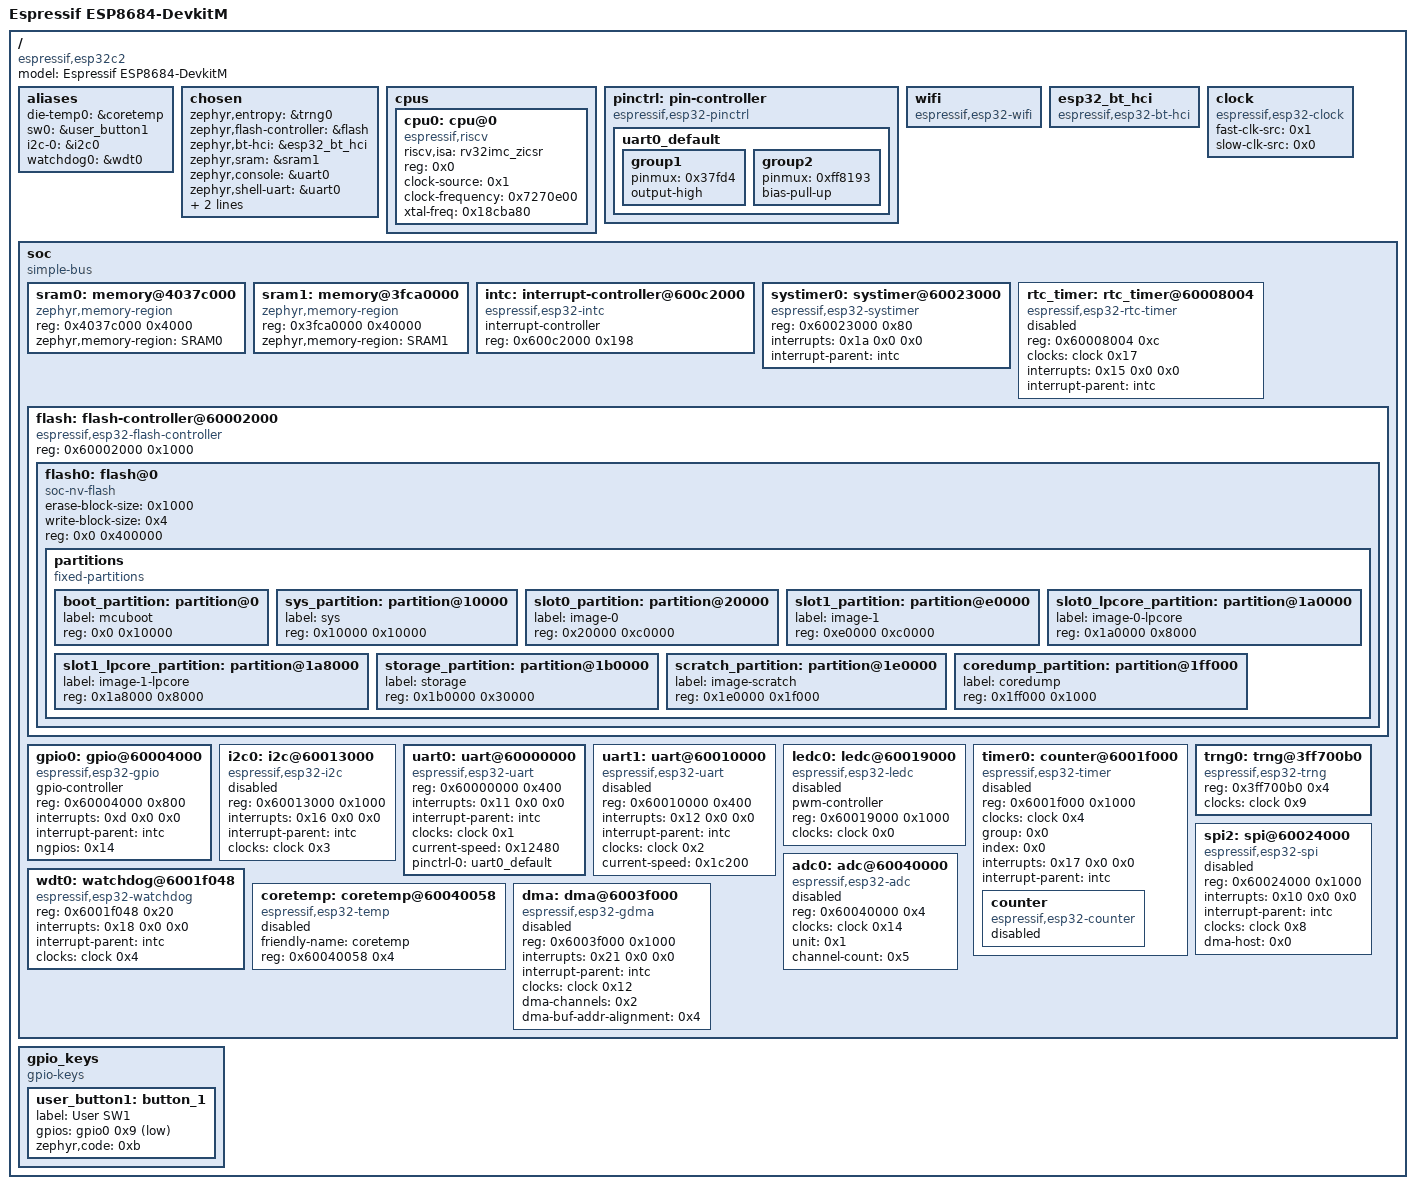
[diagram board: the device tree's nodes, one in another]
/dts-v1/;

/* node '/' defined in zephyr/dts/riscv/espressif/esp32c2/esp32c2_common.dtsi:15 */
/ {
	#address-cells = < 0x1 >;            /* in zephyr/dts/riscv/espressif/esp32c2/esp32c2_common.dtsi:16 */
	#size-cells = < 0x1 >;               /* in zephyr/dts/riscv/espressif/esp32c2/esp32c2_common.dtsi:17 */
	model = "Espressif ESP8684-DevkitM"; /* in zephyr/boards/espressif/esp8684_devkitm/esp8684_devkitm.dts:15 */
	compatible = "espressif,esp32c2";    /* in zephyr/boards/espressif/esp8684_devkitm/esp8684_devkitm.dts:16 */

	/* node '/aliases' defined in zephyr/dts/riscv/espressif/esp32c2/esp32c2_common.dtsi:19 */
	aliases {
		die-temp0 = &coretemp; /* in zephyr/dts/riscv/espressif/esp32c2/esp32c2_common.dtsi:20 */
		sw0 = &user_button1;   /* in zephyr/boards/espressif/esp8684_devkitm/esp8684_devkitm.dts:27 */
		i2c-0 = &i2c0;         /* in zephyr/boards/espressif/esp8684_devkitm/esp8684_devkitm.dts:28 */
		watchdog0 = &wdt0;     /* in zephyr/boards/espressif/esp8684_devkitm/esp8684_devkitm.dts:29 */
	};

	/* node '/chosen' defined in zephyr/dts/riscv/espressif/esp32c2/esp32c2_common.dtsi:23 */
	chosen {
		zephyr,entropy = &trng0;                  /* in zephyr/dts/riscv/espressif/esp32c2/esp32c2_common.dtsi:24 */
		zephyr,flash-controller = &flash;         /* in zephyr/dts/riscv/espressif/esp32c2/esp32c2_common.dtsi:25 */
		zephyr,bt-hci = &esp32_bt_hci;            /* in zephyr/dts/riscv/espressif/esp32c2/esp32c2_common.dtsi:26 */
		zephyr,sram = &sram1;                     /* in zephyr/boards/espressif/esp8684_devkitm/esp8684_devkitm.dts:19 */
		zephyr,console = &uart0;                  /* in zephyr/boards/espressif/esp8684_devkitm/esp8684_devkitm.dts:20 */
		zephyr,shell-uart = &uart0;               /* in zephyr/boards/espressif/esp8684_devkitm/esp8684_devkitm.dts:21 */
		zephyr,flash = &flash0;                   /* in zephyr/boards/espressif/esp8684_devkitm/esp8684_devkitm.dts:22 */
		zephyr,code-partition = &slot0_partition; /* in zephyr/boards/espressif/esp8684_devkitm/esp8684_devkitm.dts:23 */
	};

	/* node '/cpus' defined in zephyr/dts/riscv/espressif/esp32c2/esp32c2_common.dtsi:29 */
	cpus {
		#address-cells = < 0x1 >; /* in zephyr/dts/riscv/espressif/esp32c2/esp32c2_common.dtsi:30 */
		#size-cells = < 0x0 >;    /* in zephyr/dts/riscv/espressif/esp32c2/esp32c2_common.dtsi:31 */

		/* node '/cpus/cpu@0' defined in zephyr/dts/riscv/espressif/esp32c2/esp32c2_common.dtsi:33 */
		cpu0: cpu@0 {
			device_type = "cpu";             /* in zephyr/dts/riscv/espressif/esp32c2/esp32c2_common.dtsi:34 */
			compatible = "espressif,riscv",
			             "riscv";            /* in zephyr/dts/riscv/espressif/esp32c2/esp32c2_common.dtsi:35 */
			riscv,isa = "rv32imc_zicsr";     /* in zephyr/dts/riscv/espressif/esp32c2/esp32c2_common.dtsi:36 */
			reg = < 0x0 >;                   /* in zephyr/dts/riscv/espressif/esp32c2/esp32c2_common.dtsi:37 */
			clock-source = < 0x1 >;          /* in zephyr/dts/riscv/espressif/esp32c2/esp32c2_common.dtsi:38 */
			clock-frequency = < 0x7270e00 >; /* in zephyr/dts/riscv/espressif/esp32c2/esp32c2_common.dtsi:39 */
			xtal-freq = < 0x18cba80 >;       /* in zephyr/dts/riscv/espressif/esp32c2/esp32c2_common.dtsi:40 */
		};
	};

	/* node '/pin-controller' defined in zephyr/dts/riscv/espressif/esp32c2/esp32c2_common.dtsi:44 */
	pinctrl: pin-controller {
		compatible = "espressif,esp32-pinctrl"; /* in zephyr/dts/riscv/espressif/esp32c2/esp32c2_common.dtsi:45 */
		status = "okay";                        /* in zephyr/dts/riscv/espressif/esp32c2/esp32c2_common.dtsi:46 */

		/* node '/pin-controller/uart0_default' defined in zephyr/boards/espressif/esp8684_devkitm/esp8684_devkitm-pinctrl.dtsi:12 */
		uart0_default: uart0_default {
			phandle = < 0x3 >; /* in zephyr/boards/espressif/esp8684_devkitm/esp8684_devkitm.dts:46 */

			/* node '/pin-controller/uart0_default/group1' defined in zephyr/boards/espressif/esp8684_devkitm/esp8684_devkitm-pinctrl.dtsi:13 */
			group1 {
				pinmux = < 0x37fd4 >; /* in zephyr/boards/espressif/esp8684_devkitm/esp8684_devkitm-pinctrl.dtsi:14 */
				output-high;          /* in zephyr/boards/espressif/esp8684_devkitm/esp8684_devkitm-pinctrl.dtsi:15 */
			};

			/* node '/pin-controller/uart0_default/group2' defined in zephyr/boards/espressif/esp8684_devkitm/esp8684_devkitm-pinctrl.dtsi:18 */
			group2 {
				pinmux = < 0xff8193 >; /* in zephyr/boards/espressif/esp8684_devkitm/esp8684_devkitm-pinctrl.dtsi:19 */
				bias-pull-up;          /* in zephyr/boards/espressif/esp8684_devkitm/esp8684_devkitm-pinctrl.dtsi:20 */
			};
		};
	};

	/* node '/wifi' defined in zephyr/dts/riscv/espressif/esp32c2/esp32c2_common.dtsi:49 */
	wifi: wifi {
		compatible = "espressif,esp32-wifi"; /* in zephyr/dts/riscv/espressif/esp32c2/esp32c2_common.dtsi:50 */
		status = "okay";                     /* in zephyr/boards/espressif/esp8684_devkitm/esp8684_devkitm.dts:67 */
	};

	/* node '/esp32_bt_hci' defined in zephyr/dts/riscv/espressif/esp32c2/esp32c2_common.dtsi:54 */
	esp32_bt_hci: esp32_bt_hci {
		compatible = "espressif,esp32-bt-hci"; /* in zephyr/dts/riscv/espressif/esp32c2/esp32c2_common.dtsi:55 */
		status = "okay";                       /* in zephyr/boards/espressif/esp8684_devkitm/esp8684_devkitm.dts:71 */
	};

	/* node '/clock' defined in zephyr/dts/riscv/espressif/esp32c2/esp32c2_common.dtsi:59 */
	clock: clock {
		compatible = "espressif,esp32-clock"; /* in zephyr/dts/riscv/espressif/esp32c2/esp32c2_common.dtsi:60 */
		fast-clk-src = < 0x1 >;               /* in zephyr/dts/riscv/espressif/esp32c2/esp32c2_common.dtsi:61 */
		slow-clk-src = < 0x0 >;               /* in zephyr/dts/riscv/espressif/esp32c2/esp32c2_common.dtsi:62 */
		#clock-cells = < 0x1 >;               /* in zephyr/dts/riscv/espressif/esp32c2/esp32c2_common.dtsi:63 */
		status = "okay";                      /* in zephyr/dts/riscv/espressif/esp32c2/esp32c2_common.dtsi:64 */
		phandle = < 0x2 >;                    /* in zephyr/dts/riscv/espressif/esp32c2/esp32c2_common.dtsi:105 */
	};

	/* node '/soc' defined in zephyr/dts/riscv/espressif/esp32c2/esp32c2_common.dtsi:67 */
	soc {
		#address-cells = < 0x1 >;  /* in zephyr/dts/riscv/espressif/esp32c2/esp32c2_common.dtsi:68 */
		#size-cells = < 0x1 >;     /* in zephyr/dts/riscv/espressif/esp32c2/esp32c2_common.dtsi:69 */
		compatible = "simple-bus"; /* in zephyr/dts/riscv/espressif/esp32c2/esp32c2_common.dtsi:70 */
		ranges;                    /* in zephyr/dts/riscv/espressif/esp32c2/esp32c2_common.dtsi:71 */

		/* node '/soc/memory@4037c000' defined in zephyr/dts/riscv/espressif/esp32c2/esp32c2_common.dtsi:73 */
		sram0: memory@4037c000 {
			compatible = "zephyr,memory-region",
			             "mmio-sram";            /* in zephyr/dts/riscv/espressif/esp32c2/esp32c2_common.dtsi:74 */
			reg = < 0x4037c000 0x4000 >;         /* in zephyr/dts/riscv/espressif/esp32c2/esp32c2_common.dtsi:75 */
			zephyr,memory-region = "SRAM0";      /* in zephyr/dts/riscv/espressif/esp32c2/esp32c2_common.dtsi:76 */
		};

		/* node '/soc/memory@3fca0000' defined in zephyr/dts/riscv/espressif/esp32c2/esp32c2_common.dtsi:79 */
		sram1: memory@3fca0000 {
			compatible = "zephyr,memory-region",
			             "mmio-sram";            /* in zephyr/dts/riscv/espressif/esp32c2/esp32c2_common.dtsi:80 */
			reg = < 0x3fca0000 0x40000 >;        /* in zephyr/dts/riscv/espressif/esp32c2/esp32c2_common.dtsi:81 */
			zephyr,memory-region = "SRAM1";      /* in zephyr/dts/riscv/espressif/esp32c2/esp32c2_common.dtsi:82 */
		};

		/* node '/soc/interrupt-controller@600c2000' defined in zephyr/dts/riscv/espressif/esp32c2/esp32c2_common.dtsi:85 */
		intc: interrupt-controller@600c2000 {
			compatible = "espressif,esp32-intc"; /* in zephyr/dts/riscv/espressif/esp32c2/esp32c2_common.dtsi:86 */
			#address-cells = < 0x0 >;            /* in zephyr/dts/riscv/espressif/esp32c2/esp32c2_common.dtsi:87 */
			#interrupt-cells = < 0x3 >;          /* in zephyr/dts/riscv/espressif/esp32c2/esp32c2_common.dtsi:88 */
			interrupt-controller;                /* in zephyr/dts/riscv/espressif/esp32c2/esp32c2_common.dtsi:89 */
			reg = < 0x600c2000 0x198 >;          /* in zephyr/dts/riscv/espressif/esp32c2/esp32c2_common.dtsi:90 */
			status = "okay";                     /* in zephyr/dts/riscv/espressif/esp32c2/esp32c2_common.dtsi:91 */
			phandle = < 0x1 >;                   /* in zephyr/dts/riscv/espressif/esp32c2/esp32c2_common.dtsi:98 */
		};

		/* node '/soc/systimer@60023000' defined in zephyr/dts/riscv/espressif/esp32c2/esp32c2_common.dtsi:94 */
		systimer0: systimer@60023000 {
			compatible = "espressif,esp32-systimer"; /* in zephyr/dts/riscv/espressif/esp32c2/esp32c2_common.dtsi:95 */
			reg = < 0x60023000 0x80 >;               /* in zephyr/dts/riscv/espressif/esp32c2/esp32c2_common.dtsi:96 */
			interrupts = < 0x1a 0x0 0x0 >;           /* in zephyr/dts/riscv/espressif/esp32c2/esp32c2_common.dtsi:97 */
			interrupt-parent = < &intc >;            /* in zephyr/dts/riscv/espressif/esp32c2/esp32c2_common.dtsi:98 */
			status = "okay";                         /* in zephyr/dts/riscv/espressif/esp32c2/esp32c2_common.dtsi:99 */
		};

		/* node '/soc/rtc_timer@60008004' defined in zephyr/dts/riscv/espressif/esp32c2/esp32c2_common.dtsi:102 */
		rtc_timer: rtc_timer@60008004 {
			reg = < 0x60008004 0xc >;                 /* in zephyr/dts/riscv/espressif/esp32c2/esp32c2_common.dtsi:103 */
			compatible = "espressif,esp32-rtc-timer"; /* in zephyr/dts/riscv/espressif/esp32c2/esp32c2_common.dtsi:104 */
			clocks = < &clock 0x17 >;                 /* in zephyr/dts/riscv/espressif/esp32c2/esp32c2_common.dtsi:105 */
			interrupts = < 0x15 0x0 0x0 >;            /* in zephyr/dts/riscv/espressif/esp32c2/esp32c2_common.dtsi:106 */
			interrupt-parent = < &intc >;             /* in zephyr/dts/riscv/espressif/esp32c2/esp32c2_common.dtsi:107 */
			status = "disabled";                      /* in zephyr/dts/riscv/espressif/esp32c2/esp32c2_common.dtsi:108 */
		};

		/* node '/soc/flash-controller@60002000' defined in zephyr/dts/riscv/espressif/esp32c2/esp32c2_common.dtsi:111 */
		flash: flash-controller@60002000 {
			compatible = "espressif,esp32-flash-controller"; /* in zephyr/dts/riscv/espressif/esp32c2/esp32c2_common.dtsi:112 */
			reg = < 0x60002000 0x1000 >;                     /* in zephyr/dts/riscv/espressif/esp32c2/esp32c2_common.dtsi:113 */
			#address-cells = < 0x1 >;                        /* in zephyr/dts/riscv/espressif/esp32c2/esp32c2_common.dtsi:115 */
			#size-cells = < 0x1 >;                           /* in zephyr/dts/riscv/espressif/esp32c2/esp32c2_common.dtsi:116 */

			/* node '/soc/flash-controller@60002000/flash@0' defined in zephyr/dts/riscv/espressif/esp32c2/esp32c2_common.dtsi:118 */
			flash0: flash@0 {
				compatible = "soc-nv-flash";   /* in zephyr/dts/riscv/espressif/esp32c2/esp32c2_common.dtsi:119 */
				erase-block-size = < 0x1000 >; /* in zephyr/dts/riscv/espressif/esp32c2/esp32c2_common.dtsi:120 */
				write-block-size = < 0x4 >;    /* in zephyr/dts/riscv/espressif/esp32c2/esp32c2_common.dtsi:121 */
				reg = < 0x0 0x400000 >;        /* in zephyr/dts/riscv/espressif/esp32c2/esp8684_mini_h4.dtsi:11 */

				/* node '/soc/flash-controller@60002000/flash@0/partitions' defined in zephyr/dts/vendor/espressif/partitions_0x0_default_2M.dtsi:8 */
				partitions {
					compatible = "fixed-partitions"; /* in zephyr/dts/vendor/espressif/partitions_0x0_default_2M.dtsi:9 */
					#address-cells = < 0x1 >;        /* in zephyr/dts/vendor/espressif/partitions_0x0_default_2M.dtsi:10 */
					#size-cells = < 0x1 >;           /* in zephyr/dts/vendor/espressif/partitions_0x0_default_2M.dtsi:11 */

					/* node '/soc/flash-controller@60002000/flash@0/partitions/partition@0' defined in zephyr/dts/vendor/espressif/partitions_0x0_default_2M.dtsi:13 */
					boot_partition: partition@0 {
						label = "mcuboot";     /* in zephyr/dts/vendor/espressif/partitions_0x0_default_2M.dtsi:14 */
						reg = < 0x0 0x10000 >; /* in zephyr/dts/vendor/espressif/partitions_0x0_default_2M.dtsi:15 */
					};

					/* node '/soc/flash-controller@60002000/flash@0/partitions/partition@10000' defined in zephyr/dts/vendor/espressif/partitions_0x0_default_2M.dtsi:18 */
					sys_partition: partition@10000 {
						label = "sys";             /* in zephyr/dts/vendor/espressif/partitions_0x0_default_2M.dtsi:19 */
						reg = < 0x10000 0x10000 >; /* in zephyr/dts/vendor/espressif/partitions_0x0_default_2M.dtsi:20 */
					};

					/* node '/soc/flash-controller@60002000/flash@0/partitions/partition@20000' defined in zephyr/dts/vendor/espressif/partitions_0x0_default_2M.dtsi:23 */
					slot0_partition: partition@20000 {
						label = "image-0";         /* in zephyr/dts/vendor/espressif/partitions_0x0_default_2M.dtsi:24 */
						reg = < 0x20000 0xc0000 >; /* in zephyr/dts/vendor/espressif/partitions_0x0_default_2M.dtsi:25 */
					};

					/* node '/soc/flash-controller@60002000/flash@0/partitions/partition@e0000' defined in zephyr/dts/vendor/espressif/partitions_0x0_default_2M.dtsi:28 */
					slot1_partition: partition@e0000 {
						label = "image-1";         /* in zephyr/dts/vendor/espressif/partitions_0x0_default_2M.dtsi:29 */
						reg = < 0xe0000 0xc0000 >; /* in zephyr/dts/vendor/espressif/partitions_0x0_default_2M.dtsi:30 */
					};

					/* node '/soc/flash-controller@60002000/flash@0/partitions/partition@1a0000' defined in zephyr/dts/vendor/espressif/partitions_0x0_default_2M.dtsi:33 */
					slot0_lpcore_partition: partition@1a0000 {
						label = "image-0-lpcore";  /* in zephyr/dts/vendor/espressif/partitions_0x0_default_2M.dtsi:34 */
						reg = < 0x1a0000 0x8000 >; /* in zephyr/dts/vendor/espressif/partitions_0x0_default_2M.dtsi:35 */
					};

					/* node '/soc/flash-controller@60002000/flash@0/partitions/partition@1a8000' defined in zephyr/dts/vendor/espressif/partitions_0x0_default_2M.dtsi:38 */
					slot1_lpcore_partition: partition@1a8000 {
						label = "image-1-lpcore";  /* in zephyr/dts/vendor/espressif/partitions_0x0_default_2M.dtsi:39 */
						reg = < 0x1a8000 0x8000 >; /* in zephyr/dts/vendor/espressif/partitions_0x0_default_2M.dtsi:40 */
					};

					/* node '/soc/flash-controller@60002000/flash@0/partitions/partition@1b0000' defined in zephyr/dts/vendor/espressif/partitions_0x0_default_2M.dtsi:43 */
					storage_partition: partition@1b0000 {
						label = "storage";          /* in zephyr/dts/vendor/espressif/partitions_0x0_default_2M.dtsi:44 */
						reg = < 0x1b0000 0x30000 >; /* in zephyr/dts/vendor/espressif/partitions_0x0_default_2M.dtsi:45 */
					};

					/* node '/soc/flash-controller@60002000/flash@0/partitions/partition@1e0000' defined in zephyr/dts/vendor/espressif/partitions_0x0_default_2M.dtsi:48 */
					scratch_partition: partition@1e0000 {
						label = "image-scratch";    /* in zephyr/dts/vendor/espressif/partitions_0x0_default_2M.dtsi:49 */
						reg = < 0x1e0000 0x1f000 >; /* in zephyr/dts/vendor/espressif/partitions_0x0_default_2M.dtsi:50 */
					};

					/* node '/soc/flash-controller@60002000/flash@0/partitions/partition@1ff000' defined in zephyr/dts/vendor/espressif/partitions_0x0_default_2M.dtsi:53 */
					coredump_partition: partition@1ff000 {
						label = "coredump";        /* in zephyr/dts/vendor/espressif/partitions_0x0_default_2M.dtsi:54 */
						reg = < 0x1ff000 0x1000 >; /* in zephyr/dts/vendor/espressif/partitions_0x0_default_2M.dtsi:55 */
					};
				};
			};
		};

		/* node '/soc/gpio@60004000' defined in zephyr/dts/riscv/espressif/esp32c2/esp32c2_common.dtsi:126 */
		gpio0: gpio@60004000 {
			compatible = "espressif,esp32-gpio"; /* in zephyr/dts/riscv/espressif/esp32c2/esp32c2_common.dtsi:127 */
			gpio-controller;                     /* in zephyr/dts/riscv/espressif/esp32c2/esp32c2_common.dtsi:128 */
			#gpio-cells = < 0x2 >;               /* in zephyr/dts/riscv/espressif/esp32c2/esp32c2_common.dtsi:129 */
			reg = < 0x60004000 0x800 >;          /* in zephyr/dts/riscv/espressif/esp32c2/esp32c2_common.dtsi:130 */
			interrupts = < 0xd 0x0 0x0 >;        /* in zephyr/dts/riscv/espressif/esp32c2/esp32c2_common.dtsi:131 */
			interrupt-parent = < &intc >;        /* in zephyr/dts/riscv/espressif/esp32c2/esp32c2_common.dtsi:132 */
			ngpios = < 0x14 >;                   /* in zephyr/dts/riscv/espressif/esp32c2/esp32c2_common.dtsi:138 */
			status = "okay";                     /* in zephyr/boards/espressif/esp8684_devkitm/esp8684_devkitm.dts:55 */
			phandle = < 0x4 >;                   /* in zephyr/boards/espressif/esp8684_devkitm/esp8684_devkitm.dts:37 */
		};

		/* node '/soc/i2c@60013000' defined in zephyr/dts/riscv/espressif/esp32c2/esp32c2_common.dtsi:141 */
		i2c0: i2c@60013000 {
			compatible = "espressif,esp32-i2c"; /* in zephyr/dts/riscv/espressif/esp32c2/esp32c2_common.dtsi:142 */
			#address-cells = < 0x1 >;           /* in zephyr/dts/riscv/espressif/esp32c2/esp32c2_common.dtsi:143 */
			#size-cells = < 0x0 >;              /* in zephyr/dts/riscv/espressif/esp32c2/esp32c2_common.dtsi:144 */
			reg = < 0x60013000 0x1000 >;        /* in zephyr/dts/riscv/espressif/esp32c2/esp32c2_common.dtsi:145 */
			interrupts = < 0x16 0x0 0x0 >;      /* in zephyr/dts/riscv/espressif/esp32c2/esp32c2_common.dtsi:146 */
			interrupt-parent = < &intc >;       /* in zephyr/dts/riscv/espressif/esp32c2/esp32c2_common.dtsi:147 */
			clocks = < &clock 0x3 >;            /* in zephyr/dts/riscv/espressif/esp32c2/esp32c2_common.dtsi:148 */
			status = "disabled";                /* in zephyr/dts/riscv/espressif/esp32c2/esp32c2_common.dtsi:149 */
		};

		/* node '/soc/uart@60000000' defined in zephyr/dts/riscv/espressif/esp32c2/esp32c2_common.dtsi:152 */
		uart0: uart@60000000 {
			compatible = "espressif,esp32-uart"; /* in zephyr/dts/riscv/espressif/esp32c2/esp32c2_common.dtsi:153 */
			reg = < 0x60000000 0x400 >;          /* in zephyr/dts/riscv/espressif/esp32c2/esp32c2_common.dtsi:154 */
			interrupts = < 0x11 0x0 0x0 >;       /* in zephyr/dts/riscv/espressif/esp32c2/esp32c2_common.dtsi:156 */
			interrupt-parent = < &intc >;        /* in zephyr/dts/riscv/espressif/esp32c2/esp32c2_common.dtsi:157 */
			clocks = < &clock 0x1 >;             /* in zephyr/dts/riscv/espressif/esp32c2/esp32c2_common.dtsi:158 */
			status = "okay";                     /* in zephyr/boards/espressif/esp8684_devkitm/esp8684_devkitm.dts:44 */
			current-speed = < 0x12480 >;         /* in zephyr/boards/espressif/esp8684_devkitm/esp8684_devkitm.dts:45 */
			pinctrl-0 = < &uart0_default >;      /* in zephyr/boards/espressif/esp8684_devkitm/esp8684_devkitm.dts:46 */
			pinctrl-names = "default";           /* in zephyr/boards/espressif/esp8684_devkitm/esp8684_devkitm.dts:47 */
		};

		/* node '/soc/uart@60010000' defined in zephyr/dts/riscv/espressif/esp32c2/esp32c2_common.dtsi:161 */
		uart1: uart@60010000 {
			compatible = "espressif,esp32-uart"; /* in zephyr/dts/riscv/espressif/esp32c2/esp32c2_common.dtsi:162 */
			reg = < 0x60010000 0x400 >;          /* in zephyr/dts/riscv/espressif/esp32c2/esp32c2_common.dtsi:163 */
			status = "disabled";                 /* in zephyr/dts/riscv/espressif/esp32c2/esp32c2_common.dtsi:164 */
			interrupts = < 0x12 0x0 0x0 >;       /* in zephyr/dts/riscv/espressif/esp32c2/esp32c2_common.dtsi:165 */
			interrupt-parent = < &intc >;        /* in zephyr/dts/riscv/espressif/esp32c2/esp32c2_common.dtsi:166 */
			clocks = < &clock 0x2 >;             /* in zephyr/dts/riscv/espressif/esp32c2/esp32c2_common.dtsi:167 */
			current-speed = < 0x1c200 >;         /* in zephyr/dts/riscv/espressif/esp32c2/esp32c2_common.dtsi:168 */
		};

		/* node '/soc/ledc@60019000' defined in zephyr/dts/riscv/espressif/esp32c2/esp32c2_common.dtsi:171 */
		ledc0: ledc@60019000 {
			compatible = "espressif,esp32-ledc"; /* in zephyr/dts/riscv/espressif/esp32c2/esp32c2_common.dtsi:172 */
			pwm-controller;                      /* in zephyr/dts/riscv/espressif/esp32c2/esp32c2_common.dtsi:173 */
			#pwm-cells = < 0x3 >;                /* in zephyr/dts/riscv/espressif/esp32c2/esp32c2_common.dtsi:174 */
			reg = < 0x60019000 0x1000 >;         /* in zephyr/dts/riscv/espressif/esp32c2/esp32c2_common.dtsi:175 */
			clocks = < &clock 0x0 >;             /* in zephyr/dts/riscv/espressif/esp32c2/esp32c2_common.dtsi:176 */
			status = "disabled";                 /* in zephyr/dts/riscv/espressif/esp32c2/esp32c2_common.dtsi:177 */
		};

		/* node '/soc/counter@6001f000' defined in zephyr/dts/riscv/espressif/esp32c2/esp32c2_common.dtsi:180 */
		timer0: counter@6001f000 {
			compatible = "espressif,esp32-timer"; /* in zephyr/dts/riscv/espressif/esp32c2/esp32c2_common.dtsi:181 */
			reg = < 0x6001f000 0x1000 >;          /* in zephyr/dts/riscv/espressif/esp32c2/esp32c2_common.dtsi:182 */
			clocks = < &clock 0x4 >;              /* in zephyr/dts/riscv/espressif/esp32c2/esp32c2_common.dtsi:183 */
			group = < 0x0 >;                      /* in zephyr/dts/riscv/espressif/esp32c2/esp32c2_common.dtsi:184 */
			index = < 0x0 >;                      /* in zephyr/dts/riscv/espressif/esp32c2/esp32c2_common.dtsi:185 */
			interrupts = < 0x17 0x0 0x0 >;        /* in zephyr/dts/riscv/espressif/esp32c2/esp32c2_common.dtsi:186 */
			interrupt-parent = < &intc >;         /* in zephyr/dts/riscv/espressif/esp32c2/esp32c2_common.dtsi:187 */
			status = "disabled";                  /* in zephyr/boards/espressif/esp8684_devkitm/esp8684_devkitm.dts:63 */

			/* node '/soc/counter@6001f000/counter' defined in zephyr/dts/riscv/espressif/esp32c2/esp32c2_common.dtsi:190 */
			counter {
				compatible = "espressif,esp32-counter"; /* in zephyr/dts/riscv/espressif/esp32c2/esp32c2_common.dtsi:191 */
				status = "disabled";                    /* in zephyr/dts/riscv/espressif/esp32c2/esp32c2_common.dtsi:192 */
			};
		};

		/* node '/soc/trng@3ff700b0' defined in zephyr/dts/riscv/espressif/esp32c2/esp32c2_common.dtsi:196 */
		trng0: trng@3ff700b0 {
			compatible = "espressif,esp32-trng"; /* in zephyr/dts/riscv/espressif/esp32c2/esp32c2_common.dtsi:197 */
			reg = < 0x3ff700b0 0x4 >;            /* in zephyr/dts/riscv/espressif/esp32c2/esp32c2_common.dtsi:198 */
			clocks = < &clock 0x9 >;             /* in zephyr/dts/riscv/espressif/esp32c2/esp32c2_common.dtsi:199 */
			status = "okay";                     /* in zephyr/boards/espressif/esp8684_devkitm/esp8684_devkitm.dts:51 */
		};

		/* node '/soc/spi@60024000' defined in zephyr/dts/riscv/espressif/esp32c2/esp32c2_common.dtsi:203 */
		spi2: spi@60024000 {
			compatible = "espressif,esp32-spi"; /* in zephyr/dts/riscv/espressif/esp32c2/esp32c2_common.dtsi:204 */
			reg = < 0x60024000 0x1000 >;        /* in zephyr/dts/riscv/espressif/esp32c2/esp32c2_common.dtsi:205 */
			interrupts = < 0x10 0x0 0x0 >;      /* in zephyr/dts/riscv/espressif/esp32c2/esp32c2_common.dtsi:206 */
			interrupt-parent = < &intc >;       /* in zephyr/dts/riscv/espressif/esp32c2/esp32c2_common.dtsi:207 */
			clocks = < &clock 0x8 >;            /* in zephyr/dts/riscv/espressif/esp32c2/esp32c2_common.dtsi:208 */
			dma-host = < 0x0 >;                 /* in zephyr/dts/riscv/espressif/esp32c2/esp32c2_common.dtsi:209 */
			status = "disabled";                /* in zephyr/dts/riscv/espressif/esp32c2/esp32c2_common.dtsi:210 */
		};

		/* node '/soc/watchdog@6001f048' defined in zephyr/dts/riscv/espressif/esp32c2/esp32c2_common.dtsi:213 */
		wdt0: watchdog@6001f048 {
			compatible = "espressif,esp32-watchdog"; /* in zephyr/dts/riscv/espressif/esp32c2/esp32c2_common.dtsi:214 */
			reg = < 0x6001f048 0x20 >;               /* in zephyr/dts/riscv/espressif/esp32c2/esp32c2_common.dtsi:215 */
			interrupts = < 0x18 0x0 0x0 >;           /* in zephyr/dts/riscv/espressif/esp32c2/esp32c2_common.dtsi:216 */
			interrupt-parent = < &intc >;            /* in zephyr/dts/riscv/espressif/esp32c2/esp32c2_common.dtsi:217 */
			clocks = < &clock 0x4 >;                 /* in zephyr/dts/riscv/espressif/esp32c2/esp32c2_common.dtsi:218 */
			status = "okay";                         /* in zephyr/boards/espressif/esp8684_devkitm/esp8684_devkitm.dts:59 */
		};

		/* node '/soc/coretemp@60040058' defined in zephyr/dts/riscv/espressif/esp32c2/esp32c2_common.dtsi:222 */
		coretemp: coretemp@60040058 {
			compatible = "espressif,esp32-temp"; /* in zephyr/dts/riscv/espressif/esp32c2/esp32c2_common.dtsi:223 */
			friendly-name = "coretemp";          /* in zephyr/dts/riscv/espressif/esp32c2/esp32c2_common.dtsi:224 */
			reg = < 0x60040058 0x4 >;            /* in zephyr/dts/riscv/espressif/esp32c2/esp32c2_common.dtsi:225 */
			status = "disabled";                 /* in zephyr/dts/riscv/espressif/esp32c2/esp32c2_common.dtsi:226 */
		};

		/* node '/soc/adc@60040000' defined in zephyr/dts/riscv/espressif/esp32c2/esp32c2_common.dtsi:229 */
		adc0: adc@60040000 {
			compatible = "espressif,esp32-adc"; /* in zephyr/dts/riscv/espressif/esp32c2/esp32c2_common.dtsi:230 */
			reg = < 0x60040000 0x4 >;           /* in zephyr/dts/riscv/espressif/esp32c2/esp32c2_common.dtsi:231 */
			clocks = < &clock 0x14 >;           /* in zephyr/dts/riscv/espressif/esp32c2/esp32c2_common.dtsi:232 */
			unit = < 0x1 >;                     /* in zephyr/dts/riscv/espressif/esp32c2/esp32c2_common.dtsi:233 */
			channel-count = < 0x5 >;            /* in zephyr/dts/riscv/espressif/esp32c2/esp32c2_common.dtsi:234 */
			#io-channel-cells = < 0x1 >;        /* in zephyr/dts/riscv/espressif/esp32c2/esp32c2_common.dtsi:235 */
			status = "disabled";                /* in zephyr/dts/riscv/espressif/esp32c2/esp32c2_common.dtsi:236 */
		};

		/* node '/soc/dma@6003f000' defined in zephyr/dts/riscv/espressif/esp32c2/esp32c2_common.dtsi:239 */
		dma: dma@6003f000 {
			compatible = "espressif,esp32-gdma"; /* in zephyr/dts/riscv/espressif/esp32c2/esp32c2_common.dtsi:240 */
			reg = < 0x6003f000 0x1000 >;         /* in zephyr/dts/riscv/espressif/esp32c2/esp32c2_common.dtsi:241 */
			#dma-cells = < 0x1 >;                /* in zephyr/dts/riscv/espressif/esp32c2/esp32c2_common.dtsi:242 */
			interrupts = < 0x21 0x0 0x0 >;       /* in zephyr/dts/riscv/espressif/esp32c2/esp32c2_common.dtsi:243 */
			interrupt-parent = < &intc >;        /* in zephyr/dts/riscv/espressif/esp32c2/esp32c2_common.dtsi:244 */
			clocks = < &clock 0x12 >;            /* in zephyr/dts/riscv/espressif/esp32c2/esp32c2_common.dtsi:245 */
			dma-channels = < 0x2 >;              /* in zephyr/dts/riscv/espressif/esp32c2/esp32c2_common.dtsi:246 */
			dma-buf-addr-alignment = < 0x4 >;    /* in zephyr/dts/riscv/espressif/esp32c2/esp32c2_common.dtsi:247 */
			status = "disabled";                 /* in zephyr/dts/riscv/espressif/esp32c2/esp32c2_common.dtsi:248 */
		};
	};

	/* node '/gpio_keys' defined in zephyr/boards/espressif/esp8684_devkitm/esp8684_devkitm.dts:32 */
	gpio_keys {
		compatible = "gpio-keys"; /* in zephyr/boards/espressif/esp8684_devkitm/esp8684_devkitm.dts:33 */

		/* node '/gpio_keys/button_1' defined in zephyr/boards/espressif/esp8684_devkitm/esp8684_devkitm.dts:35 */
		user_button1: button_1 {
			label = "User SW1";          /* in zephyr/boards/espressif/esp8684_devkitm/esp8684_devkitm.dts:36 */
			gpios = < &gpio0 0x9 0x11 >; /* in zephyr/boards/espressif/esp8684_devkitm/esp8684_devkitm.dts:37 */
			zephyr,code = < 0xb >;       /* in zephyr/boards/espressif/esp8684_devkitm/esp8684_devkitm.dts:38 */
		};
	};
};
